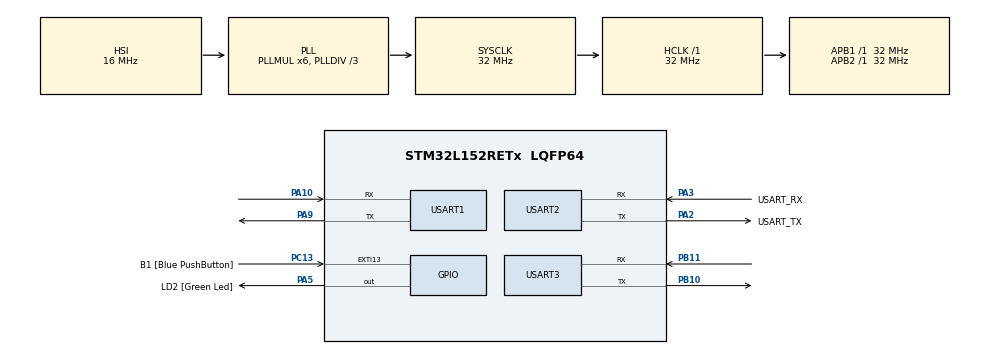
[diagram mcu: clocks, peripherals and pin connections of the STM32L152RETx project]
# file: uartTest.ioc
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FREERTOS.Tasks01=defaultTask,0,128,StartDefaultTask,Default,NULL,Dynamic,NULL,NULL
Mcu.Family=STM32L1
Mcu.Name=STM32L152RETx
Mcu.Package=LQFP64
NVIC.PriorityGroup=NVIC_PRIORITYGROUP_4
NVIC.USART1_IRQn=true\:5\:0\:false\:false\:true\:true\:true\:true
NVIC.USART2_IRQn=true\:5\:0\:false\:false\:true\:true\:true\:true
NVIC.USART3_IRQn=true\:5\:0\:false\:false\:true\:true\:true\:true
PA10.Mode=Asynchronous
PA10.Signal=USART1_RX
PA13.GPIO_Label=TMS
PA13.Mode=Serial_Wire
PA13.Signal=SYS_JTMS-SWDIO
PA14.GPIO_Label=TCK
PA14.Mode=Serial_Wire
PA14.Signal=SYS_JTCK-SWCLK
PA2.GPIO_Label=USART_TX
PA2.Mode=Asynchronous
PA2.Signal=USART2_TX
PA3.GPIO_Label=USART_RX
PA3.Mode=Asynchronous
PA3.Signal=USART2_RX
PA5.GPIO_Label=LD2 [Green Led]
PA5.Signal=GPIO_Output
PA9.Mode=Asynchronous
PA9.Signal=USART1_TX
PB10.Mode=Asynchronous
PB10.Signal=USART3_TX
PB11.Mode=Asynchronous
PB11.Signal=USART3_RX
PB3.GPIO_Label=SWO
PB3.Signal=SYS_JTDO-TRACESWO
PC13-WKUP2.GPIO_Label=B1 [Blue PushButton]
PC13-WKUP2.Signal=GPXTI13
PC14-OSC32_IN.Mode=LSE-External-Oscillator
PC14-OSC32_IN.Signal=RCC_OSC32_IN
PC15-OSC32_OUT.Mode=LSE-External-Oscillator
PC15-OSC32_OUT.Signal=RCC_OSC32_OUT
PH0-OSC_IN.Mode=HSE-External-Clock-Source
PH0-OSC_IN.Signal=RCC_OSC_IN
PH1-OSC_OUT.Signal=RCC_OSC_OUT
ProjectManager.HeapSize=0x200
ProjectManager.StackSize=0x400
ProjectManager.TargetToolchain=MDK-ARM V5
RCC.48MHZClocksFreq_Value=48000000
RCC.AHBFreq_Value=32000000
RCC.APB1Freq_Value=32000000
RCC.APB1TimFreq_Value=32000000
RCC.APB2Freq_Value=32000000
RCC.APB2TimFreq_Value=32000000
RCC.HCLKFreq_Value=32000000
RCC.HSE_VALUE=8000000
RCC.HSI_VALUE=16000000
RCC.MSI_VALUE=2097000
RCC.PLLDIV=RCC_PLL_DIV3
RCC.PLLMUL=RCC_PLL_MUL6
RCC.RTCClockSelectionVirtual=RCC_RTCCLKSOURCE_LSE
RCC.SYSCLKFreq_VALUE=32000000
RCC.SYSCLKSource=RCC_SYSCLKSOURCE_PLLCLK
RCC.USBOutput=48000000
RCC.VCOOutputFreq_Value=96000000
USART1.VirtualMode=VM_ASYNC
USART2.VirtualMode=VM_ASYNC
USART3.VirtualMode=VM_ASYNC
VP_FREERTOS_VS_CMSIS_V1.Mode=CMSIS_V1
board=NUCLEO-L152RE

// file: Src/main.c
/* USER CODE BEGIN Header */
/**
  ******************************************************************************
  * @file           : main.c
  * @brief          : Main program body
  ******************************************************************************
  * @attention
  *
  * <h2><center>&copy; Copyright (c) 2019 STMicroelectronics.
  * All rights reserved.</center></h2>
  *
  * This software component is licensed by ST under BSD 3-Clause license,
  * the "License"; You may not use this file except in compliance with the
  * License. You may obtain a copy of the License at:
  *                        opensource.org/licenses/BSD-3-Clause
  *
  ******************************************************************************
  */
/* USER CODE END Header */

#include "main.h"
#include "cmsis_os.h"

/* USER CODE BEGIN Includes */
#include "uart.h"
/* USER CODE END Includes */

UART_HandleTypeDef huart1;
UART_HandleTypeDef huart2;
UART_HandleTypeDef huart3;

osThreadId defaultTaskHandle;
//osSemaphoreId uartBinarySemHandle;

void SystemClock_Config(void);
static void MX_GPIO_Init(void);
static void MX_USART2_UART_Init(void);
static void MX_USART1_UART_Init(void);
static void MX_USART3_UART_Init(void);
void StartDefaultTask(void const * argument);

/* USER CODE BEGIN PFP */
void Debug_print(char* text){
	HAL_UART_Transmit(&huart2,(uint8_t* )text, sizeof(text),10);
}
/* USER CODE END PFP */

/* USER CODE BEGIN 0 */
	char mess[]="AT\r\n";
	uint8_t txBuff[] = {0,1,2,3,4,5,6,7,8,9};

/* USER CODE END 0 */

int main(void)
{

  /* MCU Configuration--------------------------------------------------------*/

  /* Reset of all peripherals, Initializes the Flash interface and the Systick. */
  HAL_Init();

  /* Configure the system clock */
  SystemClock_Config();

  /* Initialize all configured peripherals */
  MX_GPIO_Init();
  MX_USART2_UART_Init();
  MX_USART1_UART_Init();
  MX_USART3_UART_Init();
  /* USER CODE BEGIN 2 */
	//HAL_UART_Receive_IT(&huart2,rxBuff, 10);
	//HAL_UART_Receive_IT(&huart2,rxBuff, 10);
	//HAL_UART_Transmit_IT(&huart2,(uint8_t*)mess,sizeof(mess));

  /* USER CODE END 2 */

  /* Create the semaphores(s) */
  /* definition and creation of uartBinarySem */
  //osSemaphoreDef(uartBinarySem);
  //uartBinarySemHandle = osSemaphoreCreate(osSemaphore(uartBinarySem), 1);

  /* Create the thread(s) */
  /* definition and creation of defaultTask */
  osThreadDef(defaultTask, StartDefaultTask, osPriorityNormal, 0, 128);
  defaultTaskHandle = osThreadCreate(osThread(defaultTask), NULL);

  /* USER CODE BEGIN RTOS_THREADS */
  /* add threads, ... */
	InitUartTask();
  /* USER CODE END RTOS_THREADS */

  /* Start scheduler */
  osKernelStart();

  /* We should never get here as control is now taken by the scheduler */

  /* Infinite loop */
  while (1)
  {

  }
}

void SystemClock_Config(void)
{
  RCC_OscInitTypeDef RCC_OscInitStruct = {0};
  RCC_ClkInitTypeDef RCC_ClkInitStruct = {0};

  /** Configure the main internal regulator output voltage
  */
  __HAL_PWR_VOLTAGESCALING_CONFIG(PWR_REGULATOR_VOLTAGE_SCALE1);
  /** Initializes the CPU, AHB and APB busses clocks
  */
  RCC_OscInitStruct.OscillatorType = RCC_OSCILLATORTYPE_HSI;
  RCC_OscInitStruct.HSIState = RCC_HSI_ON;
  RCC_OscInitStruct.HSICalibrationValue = RCC_HSICALIBRATION_DEFAULT;
  RCC_OscInitStruct.PLL.PLLState = RCC_PLL_ON;
  RCC_OscInitStruct.PLL.PLLSource = RCC_PLLSOURCE_HSI;
  RCC_OscInitStruct.PLL.PLLMUL = RCC_PLL_MUL6;
  RCC_OscInitStruct.PLL.PLLDIV = RCC_PLL_DIV3;
  if (HAL_RCC_OscConfig(&RCC_OscInitStruct) != HAL_OK)
  {
    Error_Handler();
  }
  /** Initializes the CPU, AHB and APB busses clocks
  */
  RCC_ClkInitStruct.ClockType = RCC_CLOCKTYPE_HCLK|RCC_CLOCKTYPE_SYSCLK
                              |RCC_CLOCKTYPE_PCLK1|RCC_CLOCKTYPE_PCLK2;
  RCC_ClkInitStruct.SYSCLKSource = RCC_SYSCLKSOURCE_PLLCLK;
  RCC_ClkInitStruct.AHBCLKDivider = RCC_SYSCLK_DIV1;
  RCC_ClkInitStruct.APB1CLKDivider = RCC_HCLK_DIV1;
  RCC_ClkInitStruct.APB2CLKDivider = RCC_HCLK_DIV1;

  if (HAL_RCC_ClockConfig(&RCC_ClkInitStruct, FLASH_LATENCY_1) != HAL_OK)
  {
    Error_Handler();
  }
}

static void MX_USART1_UART_Init(void)
{

  huart1.Instance = USART1;
  huart1.Init.BaudRate = 115200;
  huart1.Init.WordLength = UART_WORDLENGTH_8B;
  huart1.Init.StopBits = UART_STOPBITS_1;
  huart1.Init.Parity = UART_PARITY_NONE;
  huart1.Init.Mode = UART_MODE_TX_RX;
  huart1.Init.HwFlowCtl = UART_HWCONTROL_NONE;
  huart1.Init.OverSampling = UART_OVERSAMPLING_16;
  if (HAL_UART_Init(&huart1) != HAL_OK)
  {
    Error_Handler();
  }

}

static void MX_USART2_UART_Init(void)
{

  huart2.Instance = USART2;
  huart2.Init.BaudRate = 115200;
  huart2.Init.WordLength = UART_WORDLENGTH_8B;
  huart2.Init.StopBits = UART_STOPBITS_1;
  huart2.Init.Parity = UART_PARITY_NONE;
  huart2.Init.Mode = UART_MODE_TX_RX;
  huart2.Init.HwFlowCtl = UART_HWCONTROL_NONE;
  huart2.Init.OverSampling = UART_OVERSAMPLING_16;
  if (HAL_UART_Init(&huart2) != HAL_OK)
  {
    Error_Handler();
  }

}

static void MX_USART3_UART_Init(void)
{

  huart3.Instance = USART3;
  huart3.Init.BaudRate = 115200;
  huart3.Init.WordLength = UART_WORDLENGTH_8B;
  huart3.Init.StopBits = UART_STOPBITS_1;
  huart3.Init.Parity = UART_PARITY_NONE;
  huart3.Init.Mode = UART_MODE_TX_RX;
  huart3.Init.HwFlowCtl = UART_HWCONTROL_NONE;
  huart3.Init.OverSampling = UART_OVERSAMPLING_16;
  if (HAL_UART_Init(&huart3) != HAL_OK)
  {
    Error_Handler();
  }

}

static void MX_GPIO_Init(void)
{
  GPIO_InitTypeDef GPIO_InitStruct = {0};

  /* GPIO Ports Clock Enable */
  __HAL_RCC_GPIOC_CLK_ENABLE();
  __HAL_RCC_GPIOH_CLK_ENABLE();
  __HAL_RCC_GPIOA_CLK_ENABLE();
  __HAL_RCC_GPIOB_CLK_ENABLE();

  /*Configure GPIO pin Output Level */
  HAL_GPIO_WritePin(LD2_GPIO_Port, LD2_Pin, GPIO_PIN_RESET);

  /*Configure GPIO pin : B1_Pin */
  GPIO_InitStruct.Pin = B1_Pin;
  GPIO_InitStruct.Mode = GPIO_MODE_IT_RISING;
  GPIO_InitStruct.Pull = GPIO_NOPULL;
  HAL_GPIO_Init(B1_GPIO_Port, &GPIO_InitStruct);

  /*Configure GPIO pin : LD2_Pin */
  GPIO_InitStruct.Pin = LD2_Pin;
  GPIO_InitStruct.Mode = GPIO_MODE_OUTPUT_PP;
  GPIO_InitStruct.Pull = GPIO_NOPULL;
  GPIO_InitStruct.Speed = GPIO_SPEED_FREQ_LOW;
  HAL_GPIO_Init(LD2_GPIO_Port, &GPIO_InitStruct);

}

/* USER CODE BEGIN 4 */
void HAL_UART_TxCpltCallback(UART_HandleTypeDef *UartHandle)
{
  /* Set transmission flag: trasfer complete*/
   __NOP();

}

/**
  * @brief  Rx Transfer completed callback
  * @param  UartHandle: UART handle
  * @note   This example shows a simple way to report end of DMA Rx transfer, and
  *         you can add your own implementation.
  * @retval None
  */

void vApplicationStackOverflowHook( TaskHandle_t xTask,signed char *pcTaskName ){
		Debug_print("TaskOveflow\r\n");
}
/* USER CODE END 4 */

void StartDefaultTask(void const * argument)
{

  /* USER CODE BEGIN 5 */
  /* Infinite loop */
  for(;;)
  {
		Debug_print(mess);
		HAL_UART_Transmit(&huart1, (uint8_t* )mess, sizeof(mess), 10);
		HAL_GPIO_TogglePin(LD2_GPIO_Port,LD2_Pin);
    //osDelay(200);
		vTaskDelay(500);

  }
  /* USER CODE END 5 */
}

void Error_Handler(void)
{
}

/************************ (C) COPYRIGHT STMicroelectronics *****END OF FILE****/
